# STM32N645 register map
File version: 1.0
CPU: CM55 r0p1, little endian, no MPU, FPU, vendor SysTick, 8 interrupt priority bits
Registers are 32-bit, read-write, reset 0x0 unless marked. A register's access mark holds for its fields unless they carry their own. Offsets are from the block's base; [hi:lo] are bit positions; {n}, {i} and the like mark numbered series; 'fields as' and 'values as' point back to an identical list.

## HPDMA — High-performance direct memory access controller
Base 0x48020000
Same registers: HPDMA_S 0x58020000
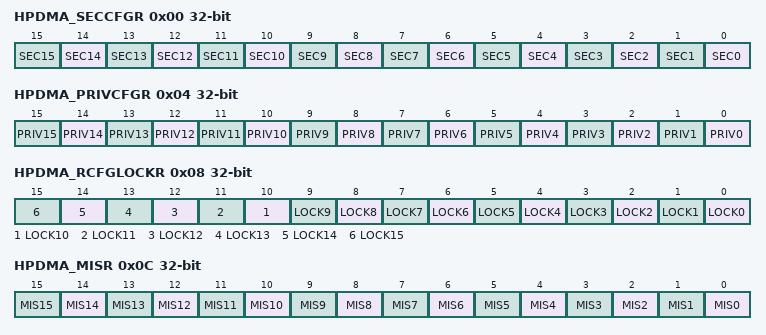
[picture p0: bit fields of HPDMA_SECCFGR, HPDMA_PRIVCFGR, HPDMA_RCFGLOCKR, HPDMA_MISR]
0x00 HPDMA_SECCFGR — HPDMA secure configuration register
  [all] fields
    0=non-secure; 1=secure
  [n] SEC{n} (n=0..15) — secure state of channel x
0x04 HPDMA_PRIVCFGR — HPDMA privileged configuration register
  [all] fields
    0=unprivileged; 1=privileged
  [n] PRIV{n} (n=0..15) — privileged state of channel x
0x08 HPDMA_RCFGLOCKR — HPDMA configuration lock register
  [all] fields
    0=secure privilege and CID configuration of the channel x is writable; 1=secure privilege and CID configuration of the channel x is not writable
  [n] LOCK{n} (n=0..15) — lock the configuration of HPDMA_SECCFGR.SECx, HPDMA_PRIVCFGR.PRIVx, and HPDMA_CxCIDCFGR until a global HPDMA reset
0x0C HPDMA_MISR ro — HPDMA non-secure masked interrupt status register
  [all] fields
    0=no interrupt occurred on channel x; 1=an interrupt occurred on channel x
  [n] MIS{n} (n=0..15) — masked interrupt status of channel x
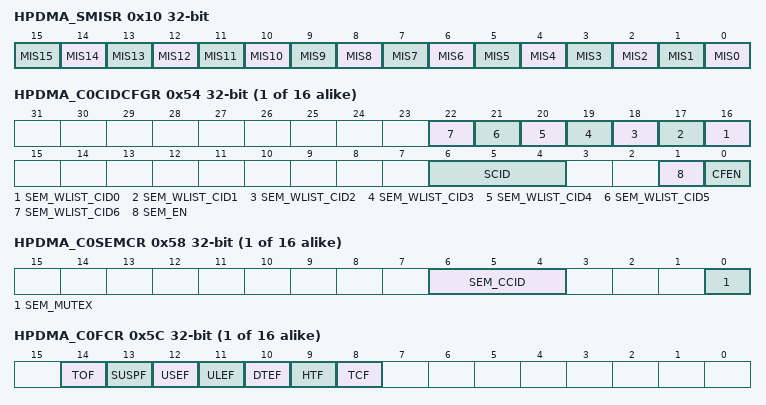
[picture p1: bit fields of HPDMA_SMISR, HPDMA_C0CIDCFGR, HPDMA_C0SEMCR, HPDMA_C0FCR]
0x10 HPDMA_SMISR ro — HPDMA secure masked interrupt status register
  [all] fields
    0=no interrupt occurred on the secure channel x; 1=an interrupt occurred on the secure channel x
  [n] MIS{n} (n=0..15) — masked interrupt status of the secure channel x
{0x50+0x80*i} HPDMA_C{i}LBAR (i=0..15) — HPDMA channel {i} linked-list base address register
  [31:16] LBA — linked-list base address of HPDMA channel x
{0x54+0x80*i} HPDMA_C{i}CIDCFGR (i=0..15) — HPDMA channel {i} CID register
  [n+16] SEM_WLIST_CID{n} (n=0..6) — white-listed CID{n} in the CID allocation pool (for when the channel x in semaphore mode)
    0=CID{n} black-listed in the semaphore-based CID allocation pool; 1=CID{n} white-listed in the semaphore-based CID allocation pool
  [6:4] SCID — allocate a static/single CID to the channel x (for when the channel x CID configuration is not in semaphore mode)
    {v}=CID{v} allocated to the channel x (v=0..6)
  [1] SEM_EN — semaphore mode enable (for the CID allocation policy to the channel x)
    0=semaphore mode disabled. CID allocation policy to the channel x is defined by SCID[1:0].; 1=semaphore mode enabled. CID allocation policy to the channel x is defined by the white-listed allocation pool SEM_WLIST_CIDx and HPDMA_CxSEMCR.SEM_MUTEX.
  [0] CFEN — CID filtering enable of the channel x
    0=CID filtering disabled for when accessing a channel x register/field; 1=CID filtering enabled for when accessing a channel x register/field
{0x58+0x80*i} HPDMA_C{i}SEMCR access per field (i=0..15) — HPDMA channel {i} semaphore control register
  [6:4] SEM_CCID ro — current CID allocated to the channel x (in semaphore mode)
    {v}=CID{v} is the last white-listed CID that took the control of the channel x (v=0..6)
  [0] SEM_MUTEX rw — mutual exclusion semaphore for the CID allocation of the channel x (in semaphore mode)
    0=B_0x0_WRITE (release the control of the channel x (in semaphore mode) to any white-listed CID); 1=B_0x1_WRITE (take the control of the channel x (in semaphore mode), from one of the white-listed CID pool)
{0x5C+0x80*i} HPDMA_C{i}FCR wo (i=0..15) — HPDMA channel {i} flag clear register
  [14] TOF — trigger overrun flag clear
    0=no effect; 1=corresponding TOF flag cleared
  [13] SUSPF — completed suspension flag clear
    0=no effect; 1=corresponding SUSPF flag cleared
  [12] USEF — user setting error flag clear
    0=no effect; 1=corresponding USEF flag cleared
  [11] ULEF — update link transfer error flag clear
    0=no effect; 1=corresponding ULEF flag cleared
  [10] DTEF — data transfer error flag clear
    0=no effect; 1=corresponding DTEF flag cleared
  [9] HTF — half transfer flag clear
    0=no effect; 1=corresponding HTF flag cleared
  [8] TCF — transfer complete flag clear
    0=no effect; 1=corresponding TCF flag cleared
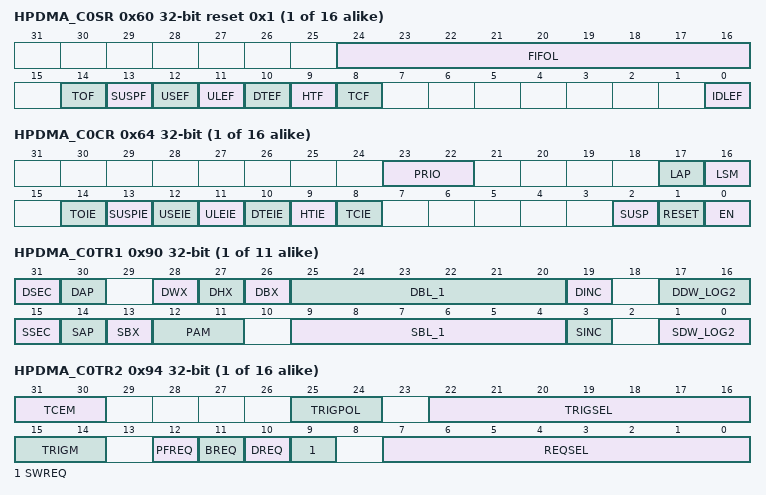
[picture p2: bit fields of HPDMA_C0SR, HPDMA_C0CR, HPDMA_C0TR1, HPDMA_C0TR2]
{0x60+0x80*i} HPDMA_C{i}SR ro reset 0x1 (i=0..15) — HPDMA channel {i} status register
  [24:16] FIFOL — monitored FIFO level
  [14] TOF — trigger overrun flag
    0=no trigger overrun event; 1=a trigger overrun event occurred
  [13] SUSPF — completed suspension flag
    0=no completed suspension event; 1=a completed suspension event occurred
  [12] USEF — user setting error flag
    0=no user setting error event; 1=a user setting error event occurred
  [11] ULEF — update link transfer error flag
    0=no update link transfer error event; 1=a master bus error event occurred while updating a linked-list register from memory
  [10] DTEF — data transfer error flag
    0=no data transfer error event; 1=a master bus error event occurred on a data transfer
  [9] HTF — half transfer flag
    0=no half transfer event; 1=an half transfer event occurred
  [8] TCF — transfer complete flag
    0=no transfer complete event; 1=a transfer complete event occurred
  [0] IDLEF — idle flag
    0=channel not in idle state; 1=channel in idle state
{0x64+0x80*i} HPDMA_C{i}CR access per field (i=0..15) — HPDMA channel {i} control register
  [23:22] PRIO rw — priority level of the channel x HPDMA transfer versus others
    0=low priority, low weight; 1=low priority, mid weight; 2=low priority, high weight; 3=high priority
  [17] LAP rw — linked-list allocated port
    0=port 0 (AXI) allocated; 1=port 1 (AHB) allocated
  [16] LSM rw — Link step mode
    0=channel executed for the full linked-list and completed at the end of the last LLI (HPDMA_CxLLR = 0). The 16 low-significant bits of the link address are null (LA[15:0] = 0) and all the update bits are null (UT1 = UB1 = UT2 = USA = UDA = ULL = 0 and UT3 = UB2 = 0 if present). Then HPDMA_CxBR1.BNDT[15:0] = 0 and HPDMA_CxBR1.BRC[10:0] = 0 if present.; 1=channel executed once for the current LLI
  [14] TOIE rw — trigger overrun interrupt enable
    0=interrupt disabled; 1=interrupt enabled
  [13] SUSPIE rw — completed suspension interrupt enable
    0=interrupt disabled; 1=interrupt enabled
  [12] USEIE rw — user setting error interrupt enable
    0=interrupt disabled; 1=interrupt enabled
  [11] ULEIE rw — update link transfer error interrupt enable
    0=interrupt disabled; 1=interrupt enabled
  [10] DTEIE rw — data transfer error interrupt enable
    0=interrupt disabled; 1=interrupt enabled
  [9] HTIE rw — half transfer complete interrupt enable
    0=interrupt disabled; 1=interrupt enabled
  [8] TCIE rw — transfer complete interrupt enable
    0=interrupt disabled; 1=interrupt enabled
  [2] SUSP rw — suspend
    0=write: resume channel, read: channel not suspended; 1=write: suspend channel, read: channel suspended
  [1] RESET wo
    0=no channel reset; 1=channel reset
  [0] EN rw — enable
    0=write: ignored, read: channel disabled; 1=write: enable channel, read: channel enabled
{0x90+0x80*i} HPDMA_C{i}TR1 (i=0..10) — HPDMA channel {i} transfer register 1
  [31] DSEC — security attribute of the HPDMA transfer to the destination
    0=HPDMA transfer non-secure; 1=HPDMA transfer secure
  [30] DAP — destination allocated port
    0=port 0 (AXI) allocated; 1=port 1 (AHB) allocated
  [28] DWX — destination word exchange
    0=no word-based exchanged within double-word; 1=the two consecutive (post PAM) words are exchanged in each destination double-word
  [27] DHX — destination half-word exchange
    0=no half-word-based exchanged within word; 1=the two consecutive (post PAM) half-words are exchanged in each destination word
  [26] DBX — destination byte exchange
    0=no byte-based exchange within half-word; 1=the two consecutive (post PAM) bytes are exchanged in each destination half-word
  [25:20] DBL_1 — destination burst length minus 1, between 0 and 63
  [19] DINC — destination incrementing burst
    0=fixed burst; 1=contiguously incremented burst
  [17:16] DDW_LOG2 — binary logarithm of the destination data width of a burst, in bytes
    0=byte; 1=half-word (2 bytes); 2=word (4 bytes); 3=If DAP = 0 (AXI), double-word (8 bytes)
  [15] SSEC — security attribute of the HPDMA transfer from the source
    0=HPDMA transfer non-secure; 1=HPDMA transfer secure
  [14] SAP — source allocated port
    0=port 0 (AXI) allocated; 1=port 1 (AHB) allocated
  [13] SBX — source byte exchange within the unaligned half-word of each source word
    0=no byte-based exchange within the unaligned half-word of each source word; 1=the two consecutive bytes within the unaligned half-word of each source word are exchanged
  [12:11] PAM — padding/alignment mode
    0=B_0x0_PAM_1 (source data is transferred as right aligned, padded with 0s up to the destination data width); 1=B_0x1_PAM_1 (source data is transferred as right aligned, sign extended up to the destination data width)
  [9:4] SBL_1 — source burst length minus 1, between 0 and 63
  [3] SINC — source incrementing burst
    0=fixed burst; 1=contiguously incremented burst
  [1:0] SDW_LOG2 — binary logarithm of the source data width of a burst in bytes
    0=byte; 1=half-word (2 bytes); 2=word (4 bytes); 3=If SAP = 0 (AXI), double-word (8 bytes)
{0x94+0x80*i} HPDMA_C{i}TR2 (i=0..15) — HPDMA channel {i} transfer register 2
  [31:30] TCEM — transfer complete event mode
    0=at block level (when HPDMA_CxBR1.BNDT[15:0] = 0): the complete (and the half) transfer event is generated at the (respectively half of the) end of a block; 1=channel x = 0 to 11, same as 00; channel x=12 to 15, at 2D/repeated block level (when HPDMA_CxBR1.BRC[10:0] = 0 and HPDMA_CxBR1.BNDT[15:0] = 0), the complete (and the half) transfer event is generated at the end (respectively half of the end) of the 2D/repeated block; 2=at LLI level: the complete transfer event is generated at the end of the LLI transfer, including the update of the LLI if any. The half transfer event is generated at the half of the LLI data transfer (the LLI data transfer being a block transfer or a 2D/repeated block transfer for channel x = 12 to 15), if any data transfer.; 3=at channel level: the complete transfer event is generated at the end of the last LLI transfer. The half transfer event is generated at the half of the data transfer of the last LLI. The last LLI updates the link address HPDMA_CxLLR.LA[15:2] to zero and clears all the HPDMA_CxLLR update bits (UT1, UT2, UB1, USA, UDA and ULL, plus UT3 and UB2 if present). If the channel transfer is continuous/infinite, no event is generated.
  [25:24] TRIGPOL — trigger event polarity
    0=no trigger (masked trigger event); 1=trigger on the rising edge; 2=trigger on the falling edge; 3=same as 00
  [22:16] TRIGSEL — trigger event input selection
  [15:14] TRIGM — trigger mode
    0=at block level: the first burst read of each block transfer is conditioned by one hit trigger (channel x = 12 to 15, for each block if a 2D/repeated block is configured with HPDMA_CxBR1.BRC[10:0] different 0); 1=channel x = 0 to 11, same as 00; channel x=12 to 15, at 2D/repeated block level, the; 2=at link level: a LLI link transfer is conditioned by one hit trigger. The LLI data transfer (if any) is not conditioned.; 3=at programmed burst level: If SWREQ = 1, each programmed burst read is conditioned by one hit trigger. If SWREQ = 0, each programmed burst that is requested by the selected peripheral, is conditioned by one hit trigger.
  [12] PFREQ — Hardware request in peripheral flow control mode
    0=the selected hardware request is driven by a peripheral with a hardware request/acknowledge protocol in HPDMA control mode. The HPDMA is programmed with HPDMA_CxCBR1.BNDT[15:0] and this is internally used by the hardware for the block transfer completion.; 1=the selected hardware request is driven by a peripheral with a hardware request/acknowledge protocol in peripheral control mode. The HPDMA block transfer can be early completed by the peripheral itself (see Section 15.3.5 for more details).
  [11] BREQ — Block hardware request
    0=the selected hardware request is driven by a peripheral with a hardware request/acknowledge protocol at a burst level; 1=the selected hardware request is driven by a peripheral with a hardware request/acknowledge protocol at a block level (see Section 15.3.4)
  [10] DREQ — destination hardware request
    0=selected hardware request driven by a source peripheral (request signal taken into account by the HPDMA transfer scheduler over the source/read port); 1=selected hardware request driven by a destination peripheral (request signal taken into account by the HPDMA transfer scheduler over the destination/write port)
  [9] SWREQ — software request
    0=no software request. The selected hardware request REQSEL[7:0] is taken into account.; 1=software request for a memory-to-memory transfer. The default selected hardware request as per REQSEL[7:0] is ignored.
  [7:0] REQSEL — hardware request selection
{0x98+0x80*i} HPDMA_C{i}BR1 (i=0..11) — HPDMA channel {i} block register 1
  [15:0] BNDT — block number of data bytes to transfer from the source
{0x9C+0x80*i} HPDMA_C{i}SAR (i=0..15) — HPDMA channel {i} source address register
  [31:0] SA — source address
{0xA0+0x80*i} HPDMA_C{i}DAR (i=0..15) — HPDMA channel {i} destination address register
  [31:0] DA — destination address
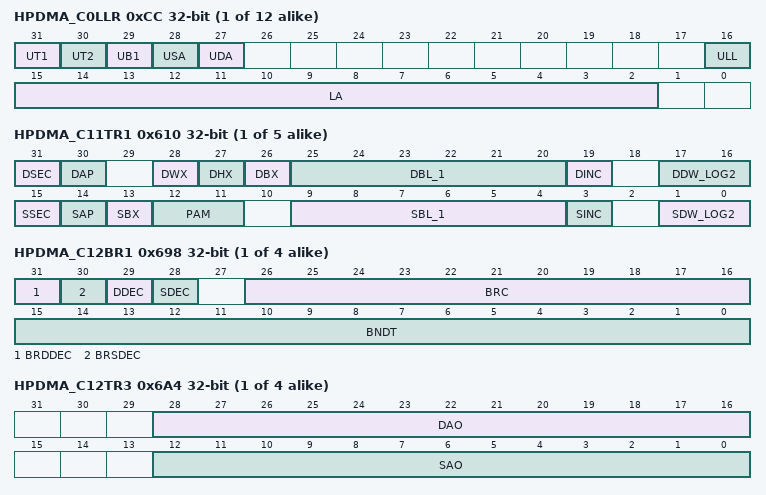
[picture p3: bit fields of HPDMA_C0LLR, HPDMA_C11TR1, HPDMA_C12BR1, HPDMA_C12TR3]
{0xCC+0x80*i} HPDMA_C{i}LLR (i=0..11) — HPDMA channel {i} linked-list address register
  [31] UT1 — Update HPDMA_CxTR1 from memory
    0=no HPDMA_CxTR1 update; 1=HPDMA_CxTR1 update
  [30] UT2 — Update HPDMA_CxTR2 from memory
    0=no HPDMA_CxTR2 update; 1=HPDMA_CxTR2 update
  [29] UB1 — Update HPDMA_CxBR1 from memory
    0=no HPDMA_CxBR1 update from memory (HPDMA_CxBR1.BNDT[15:0] restored if any link transfer); 1=HPDMA_CxBR1 update
  [28] USA — update HPDMA_CxSAR from memory
    0=no HPDMA_CxSAR update; 1=HPDMA_CxSAR update
  [27] UDA — Update HPDMA_CxDAR register from memory
    0=no HPDMA_CxDAR update; 1=HPDMA_CxDAR update
  [16] ULL — Update HPDMA_CxLLR register from memory
    0=no HPDMA_CxLLR update; 1=HPDMA_CxLLR update
  [15:2] LA — pointer (16-bit low-significant address) to the next linked-list data structure
{0x90+0x80*i} HPDMA_C{i}TR1 (i=11..15) — HPDMA channel {i} transfer register 1
  [31] DSEC — security attribute of the HPDMA transfer to the destination
    0=HPDMA transfer non-secure; 1=HPDMA transfer secure
  [30] DAP — destination allocated port
    0=port 0 (AXI) allocated; 1=port 1 (AHB) allocated
  [28] DWX — destination word exchange
    values as HPDMA_C0TR1.DWX
  [27] DHX — destination half-word exchange
    values as HPDMA_C0TR1.DHX
  [26] DBX — destination byte exchange
    values as HPDMA_C0TR1.DBX
  [25:20] DBL_1 — destination burst length minus 1, between 0 and 63
  [19] DINC — destination incrementing burst
    0=fixed burst; 1=contiguously incremented burst
  [17:16] DDW_LOG2 — binary logarithm of the destination data width of a burst, in bytes
    values as HPDMA_C0TR1.DDW_LOG2
  [15] SSEC — security attribute of the HPDMA transfer from the source
    0=HPDMA transfer non-secure; 1=HPDMA transfer secure
  [14] SAP — source allocated port
    0=port 0 (AXI) allocated; 1=port 1 (AHB) allocated
  [13] SBX — source byte exchange within the unaligned half-word of each source word
    values as HPDMA_C0TR1.SBX
  [12:11] PAM — padding/alignment mode
    0=B_0x0_PAM_1 (source data is transferred as right aligned, padded with 0s up to the destination data width); 1=B_0x1_PAM_1 (source data is transferred as right aligned, sign extended up to the destination data width); 2=B_0x2_PAM_1 (successive source data are FIFO queued and packed at the destination data width, in a left (LSB) to right (MSB) order (named little endian), before a destination transfer); 3=B_0x3_PAM_1 (successive source data are FIFO queued and packed at the destination data width, in a left (LSB) to right (MSB) order (named little endian), before a destination transfer)
  [9:4] SBL_1 — source burst length minus 1, between 0 and 63
  [3] SINC — source incrementing burst
    0=fixed burst; 1=contiguously incremented burst
  [1:0] SDW_LOG2 — binary logarithm of the source data width of a burst in bytes
    values as HPDMA_C0TR1.SDW_LOG2
{0x98+0x80*i} HPDMA_C{i}BR1 (i=12..15) — HPDMA channel {i} alternate block register 1
  [31] BRDDEC — Block repeat destination address decrement
    0=at the end of a block transfer, the HPDMA_CxDAR register is updated by adding the programmed offset HPDMA_CxBR2.BRDAO to the current HPDMA_CxDAR value (current destination address); 1=at the end of a block transfer, the HPDMA_CxDAR register is updated by subtracting the programmed offset HPDMA_CxBR2.BRDAO from the current HPDMA_CxDAR value (current destination address)
  [30] BRSDEC — Block repeat source address decrement
    0=at the end of a block transfer, the HPDMA_CxSAR register is updated by adding the programmed offset HPDMA_CxBR2.BRSAO to the current HPDMA_CxSAR value (current source address); 1=at the end of a block transfer, the HPDMA_CxSAR register is updated by subtracting the programmed offset HPDMA_CxBR2.BRSAO from the current HPDMA_CxSAR value (current source address)
  [29] DDEC — destination address decrement
    0=At the end of a programmed burst transfer to the destination, the HPDMA_CxDAR register is updated by adding the programmed offset HPDMA_CxTR3.DAO to the current HPDMA_CxDAR value (current destination address); 1=At the end of a programmed burst transfer to the destination, the HPDMA_CxDAR register is updated by subtracting the programmed offset HPDMA_CxTR3.DAO to the current HPDMA_CxDAR value (current destination address)
  [28] SDEC — source address decrement
    0=At the end of a programmed burst transfer from the source, the HPDMA_CxSAR register is updated by adding the programmed offset HPDMA_CxTR3.SAO to the current HPDMA_CxSAR value (current source address); 1=At the end of a programmed burst transfer from the source, the HPDMA_CxSAR register is updated by subtracting the programmed offset HPDMA_CxTR3.SAO to the current HPDMA_CxSAR value (current source address)
  [26:16] BRC — Block repeat counter
  [15:0] BNDT — block number of data bytes to transfer from the source
{0xA4+0x80*i} HPDMA_C{i}TR3 (i=12..15) — HPDMA channel {i} transfer register 3
  [28:16] DAO — destination address offset increment
  [12:0] SAO — source address offset increment
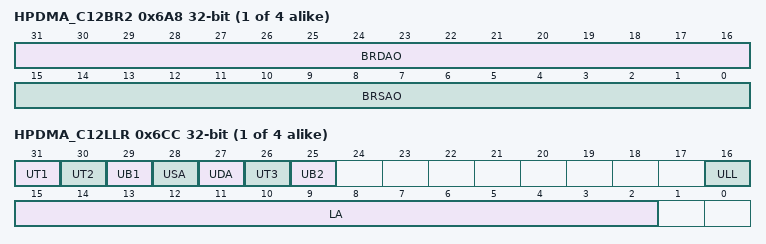
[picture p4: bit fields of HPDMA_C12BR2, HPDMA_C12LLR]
{0xA8+0x80*i} HPDMA_C{i}BR2 (i=12..15) — HPDMA channel {i} block register 2
  [31:16] BRDAO — Block repeated destination address offset
  [15:0] BRSAO — Block repeated source address offset
{0xCC+0x80*i} HPDMA_C{i}LLR (i=12..15) — HPDMA channel {i} alternate linked-list address register
  [31] UT1 — Update HPDMA_CxTR1 from memory
    0=no HPDMA_CxTR1 update; 1=HPDMA_CxTR1 update
  [30] UT2 — Update HPDMA_CxTR2 from memory
    0=no HPDMA_CxTR2 update; 1=HPDMA_CxTR2 update
  [29] UB1 — Update HPDMA_CxBR1 from memory
    values as HPDMA_C0LLR.UB1
  [28] USA — update HPDMA_CxSAR from memory
    0=no HPDMA_CxSAR update; 1=HPDMA_CxSAR update
  [27] UDA — Update HPDMA_CxDAR register from memory
    0=no HPDMA_CxDAR update; 1=HPDMA_CxDAR update
  [26] UT3 — Update HPDMA_CxTR3 from memory
    0=no HPDMA_CxTR3 update; 1=HPDMA_CxTR3 update
  [25] UB2 — Update HPDMA_CxBR2 from memory
    0=no HPDMA_CxBR2 update; 1=HPDMA_CxBR2 update
  [16] ULL — Update HPDMA_CxLLR register from memory
    0=no HPDMA_CxLLR update; 1=HPDMA_CxLLR update
  [15:2] LA — pointer (16-bit low-significant address) to the next linked-list data structure
